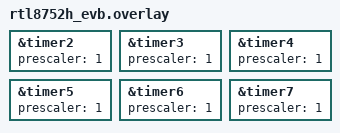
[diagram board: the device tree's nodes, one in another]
/*
 * Copyright(c) 2025 Realtek Semiconductor Corporation.
 *
 * SPDX-License-Identifier: Apache-2.0
 */

&timer2 {
	status = "okay";
	prescaler = <1>;
};

&timer3 {
	status = "okay";
	prescaler = <1>;
};

&timer4 {
	status = "okay";
	prescaler = <1>;
};

&timer5 {
	status = "okay";
	prescaler = <1>;
};

&timer6 {
	status = "okay";
	prescaler = <1>;
};

&timer7 {
	status = "okay";
	prescaler = <1>;
};
